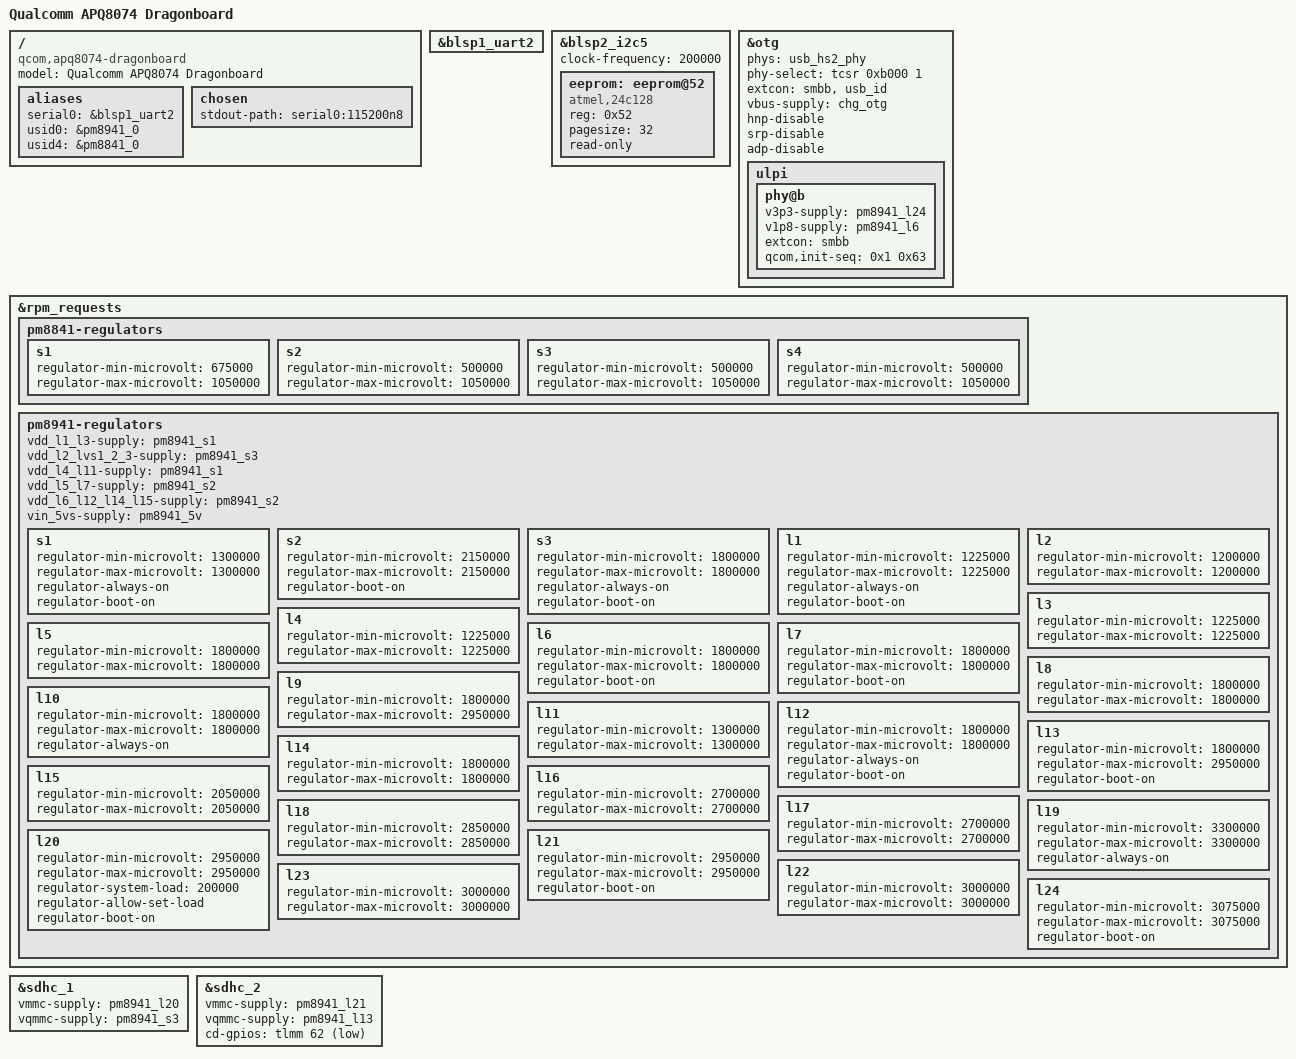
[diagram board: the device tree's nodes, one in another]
// SPDX-License-Identifier: GPL-2.0
#include "qcom-msm8974.dtsi"
#include "qcom-pm8841.dtsi"
#include "qcom-pm8941.dtsi"
#include <dt-bindings/gpio/gpio.h>

/ {
	model = "Qualcomm APQ8074 Dragonboard";
	compatible = "qcom,apq8074-dragonboard", "qcom,apq8074";

	aliases {
		serial0 = &blsp1_uart2;
		usid0 = &pm8941_0;
		usid4 = &pm8841_0;
	};

	chosen {
		stdout-path = "serial0:115200n8";
	};
};

&blsp1_uart2 {
	status = "ok";
};

&blsp2_i2c5 {
	status = "okay";
	clock-frequency = <200000>;

	eeprom: eeprom@52 {
		compatible = "atmel,24c128";
		reg = <0x52>;
		pagesize = <32>;
		read-only;
	};
};

&otg {
	status = "ok";
	phys = <&usb_hs2_phy>;
	phy-select = <&tcsr 0xb000 1>;
	extcon = <&smbb>, <&usb_id>;
	vbus-supply = <&chg_otg>;
	hnp-disable;
	srp-disable;
	adp-disable;
	ulpi {
		phy@b {
			status = "ok";
			v3p3-supply = <&pm8941_l24>;
			v1p8-supply = <&pm8941_l6>;
			extcon = <&smbb>;
			qcom,init-seq = /bits/ 8 <0x1 0x63>;
		};
	};
};

&rpm_requests {
	pm8841-regulators {
		s1 {
			regulator-min-microvolt = <675000>;
			regulator-max-microvolt = <1050000>;
		};

		s2 {
			regulator-min-microvolt = <500000>;
			regulator-max-microvolt = <1050000>;
		};

		s3 {
			regulator-min-microvolt = <500000>;
			regulator-max-microvolt = <1050000>;
		};

		s4 {
			regulator-min-microvolt = <500000>;
			regulator-max-microvolt = <1050000>;
		};
	};

	pm8941-regulators {
		vdd_l1_l3-supply = <&pm8941_s1>;
		vdd_l2_lvs1_2_3-supply = <&pm8941_s3>;
		vdd_l4_l11-supply = <&pm8941_s1>;
		vdd_l5_l7-supply = <&pm8941_s2>;
		vdd_l6_l12_l14_l15-supply = <&pm8941_s2>;
		vin_5vs-supply = <&pm8941_5v>;

		s1 {
			regulator-min-microvolt = <1300000>;
			regulator-max-microvolt = <1300000>;
			regulator-always-on;
			regulator-boot-on;
		};

		s2 {
			regulator-min-microvolt = <2150000>;
			regulator-max-microvolt = <2150000>;
			regulator-boot-on;
		};

		s3 {
			regulator-min-microvolt = <1800000>;
			regulator-max-microvolt = <1800000>;
			regulator-always-on;
			regulator-boot-on;
		};

		l1 {
			regulator-min-microvolt = <1225000>;
			regulator-max-microvolt = <1225000>;
			regulator-always-on;
			regulator-boot-on;
		};

		l2 {
			regulator-min-microvolt = <1200000>;
			regulator-max-microvolt = <1200000>;
		};

		l3 {
			regulator-min-microvolt = <1225000>;
			regulator-max-microvolt = <1225000>;
		};

		l4 {
			regulator-min-microvolt = <1225000>;
			regulator-max-microvolt = <1225000>;
		};

		l5 {
			regulator-min-microvolt = <1800000>;
			regulator-max-microvolt = <1800000>;
		};

		l6 {
			regulator-min-microvolt = <1800000>;
			regulator-max-microvolt = <1800000>;
			regulator-boot-on;
		};

		l7 {
			regulator-min-microvolt = <1800000>;
			regulator-max-microvolt = <1800000>;
			regulator-boot-on;
		};

		l8 {
			regulator-min-microvolt = <1800000>;
			regulator-max-microvolt = <1800000>;
		};

		l9 {
			regulator-min-microvolt = <1800000>;
			regulator-max-microvolt = <2950000>;
		};

		l10 {
			regulator-min-microvolt = <1800000>;
			regulator-max-microvolt = <1800000>;
			regulator-always-on;
		};

		l11 {
			regulator-min-microvolt = <1300000>;
			regulator-max-microvolt = <1300000>;
		};

		l12 {
			regulator-min-microvolt = <1800000>;
			regulator-max-microvolt = <1800000>;
			regulator-always-on;
			regulator-boot-on;
		};

		l13 {
			regulator-min-microvolt = <1800000>;
			regulator-max-microvolt = <2950000>;
			regulator-boot-on;
		};

		l14 {
			regulator-min-microvolt = <1800000>;
			regulator-max-microvolt = <1800000>;
		};

		l15 {
			regulator-min-microvolt = <2050000>;
			regulator-max-microvolt = <2050000>;
		};

		l16 {
			regulator-min-microvolt = <2700000>;
			regulator-max-microvolt = <2700000>;
		};

		l17 {
			regulator-min-microvolt = <2700000>;
			regulator-max-microvolt = <2700000>;
		};

		l18 {
			regulator-min-microvolt = <2850000>;
			regulator-max-microvolt = <2850000>;
		};

		l19 {
			regulator-min-microvolt = <3300000>;
			regulator-max-microvolt = <3300000>;
			regulator-always-on;
		};

		l20 {
			regulator-min-microvolt = <2950000>;
			regulator-max-microvolt = <2950000>;
			regulator-system-load = <200000>;
			regulator-allow-set-load;
			regulator-boot-on;
		};

		l21 {
			regulator-min-microvolt = <2950000>;
			regulator-max-microvolt = <2950000>;
			regulator-boot-on;
		};

		l22 {
			regulator-min-microvolt = <3000000>;
			regulator-max-microvolt = <3000000>;
		};

		l23 {
			regulator-min-microvolt = <3000000>;
			regulator-max-microvolt = <3000000>;
		};

		l24 {
			regulator-min-microvolt = <3075000>;
			regulator-max-microvolt = <3075000>;
			regulator-boot-on;
		};
	};
};

&sdhc_1 {
	status = "ok";

	vmmc-supply = <&pm8941_l20>;
	vqmmc-supply = <&pm8941_s3>;
};

&sdhc_2 {
	status = "ok";

	vmmc-supply = <&pm8941_l21>;
	vqmmc-supply = <&pm8941_l13>;

	cd-gpios = <&tlmm 62 GPIO_ACTIVE_LOW>;
};
